# log_engine: IP-XACT component
VLNV tenstorrent.com:ocah:log_engine:1.0

## Address spaces and blocks
log_engine_mmap.log_engine: base 'h0, range 'h80, width 64

## Registers
Registers are 32-bit, read-write, reset 0x0 unless marked. A register's access mark holds for its fields unless they carry their own. Offsets are from the block's base; lines under a group give offsets from that group; [hi:lo] are bit positions; {n}, {i} and the like mark numbered series; 'fields as' and 'values as' point back to an identical list; <NAME> marks a mode.

## log_engine_mmap.log_engine — Configuration and status registers for the UART log engine, including the log region and write pointers.
Base 0x00000000
0x00 CTRL — Control Register
  [0] EN — Log Engine Enable. When set, enables the Log Engine. When cleared, the engine stops fetching and writing, discards buffered log data and resets transfer progress. Configuration and pending LOG_LEN values are retained, so a pending entry restarts from the start of its slot when the engine is enabled again. Clearing does not wait for outstanding bus responses.
0x04 LOG_REGION_SIZE
  [19:0] LOG_REGION_SIZE — Log region size in bytes. Supported values are at most 512 KiB and aligned to 128 bytes (16 slots times the 8-byte fetch beat). If software programs a larger value, RTL clamps the effective region to 512 KiB. For a value that is not 128-byte aligned, RTL divides the effective region among the 16 slots and rounds each slot's transferable capacity down to complete 8-byte fetch beats. A requested LOG_LEN above that capacity is clamped to the capacity.
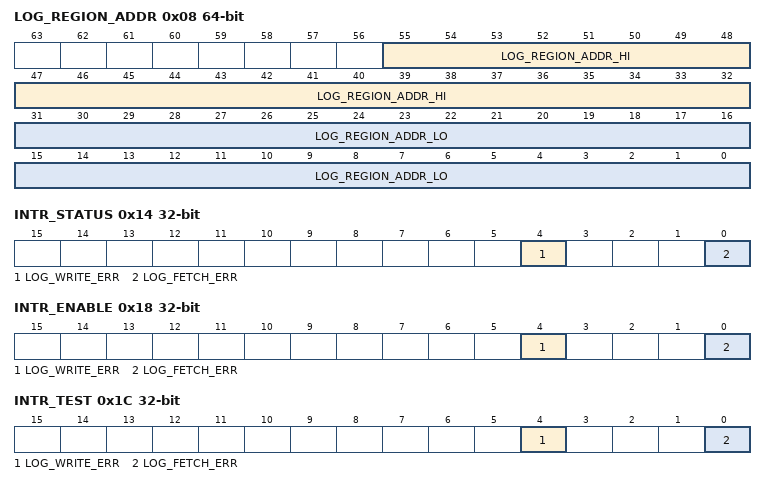
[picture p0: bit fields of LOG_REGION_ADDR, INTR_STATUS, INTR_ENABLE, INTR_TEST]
0x08 LOG_REGION_ADDR 64-bit access per field — Log Region Address Register
  [55:32] LOG_REGION_ADDR_HI rw — Log Region Start Address High. Contains fabric address bits [55:32].
  [31:0] LOG_REGION_ADDR_LO rw — Log Region Start Address Low.
0x10 LOG_WRITE_ADDR — Log Write Address Register
  [31:0] LOG_WRITE_ADDR — Log Write Address. This is the address where the log data is written to.
0x14 INTR_STATUS — Interrupt Status Register
  [4] LOG_WRITE_ERR write-1-clears — Log Write Error Interrupt. Asserted when the bus for writing log data returns an error.
  [0] LOG_FETCH_ERR write-1-clears — Log Fetch Error Interrupt. Asserted when the bus for fetching log data returns an error.
0x18 INTR_ENABLE — Interrupt Enable Register
  [4] LOG_WRITE_ERR — Log Write Error Interrupt Enable.
  [0] LOG_FETCH_ERR — Log Fetch Error Interrupt Enable.
0x1C INTR_TEST wo — Interrupt Test Register
  [4] LOG_WRITE_ERR — Log Write Error Interrupt Test. Writing `1` forces the interrupt.
  [0] LOG_FETCH_ERR — Log Fetch Error Interrupt Test. Writing `1` forces the interrupt.
{0x40+4i} LOG_CTRL[{i}] (i=0..15) — Log Control Register
  [15:0] LOG_LEN — Log Length. Writing a nonzero value representing the log length in bytes to this field starts the log transfer process. The field holds the requested length until the transfer completes, when hardware clears it to zero; it is not a remaining-byte counter. There are 16 copies of this register, each representing a log entry. The log entries go through round robin arbitration.

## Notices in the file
SPDX-License-Identifier: Apache-2.0
SPDX-FileCopyrightText: 2026 Tenstorrent USA, Inc.
